# GD32EPRTxxA register map
File version: 1.0
CPU: CM33 r0p4, little endian, MPU, FPU, 4 interrupt priority bits
Registers are 32-bit, read-write, reset 0x0 unless marked. A register's access mark holds for its fields unless they carry their own. Offsets are from the block's base; [hi:lo] are bit positions; {n}, {i} and the like mark numbered series.

## SLAVE_TIMER3 — SHRTIMER Slave TIMER3 registers(
Base 0x40017600
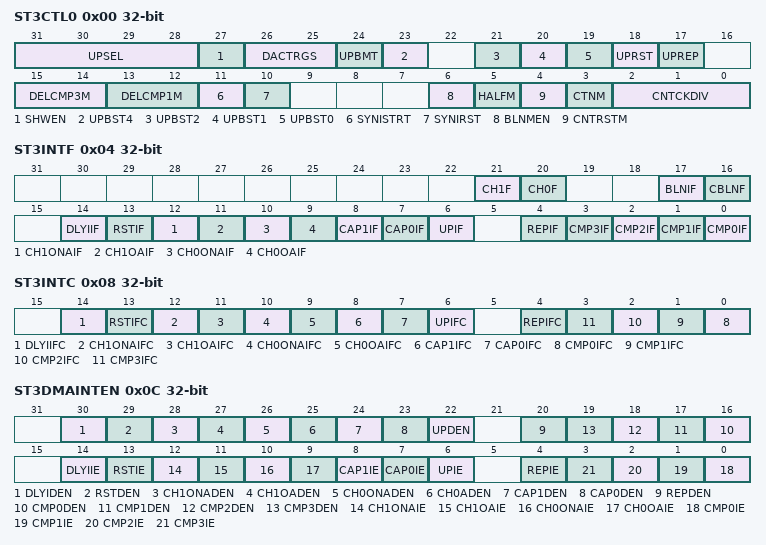
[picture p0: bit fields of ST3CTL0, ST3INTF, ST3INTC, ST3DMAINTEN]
0x00 ST3CTL0 — SHRTIMER Slave_TIMERx control register 0
  [31:28] UPSEL — Update event selection
  [27] SHWEN — Shadow registers enable
  [26:25] DACTRGS — Trigger source to DAC
  [24] UPBMT — Update by Master_TIMER update event
  [23] UPBST4 — Update by Slave_TIMER4 update event
  [21] UPBST2 — Update by Slave_TIMER2 update event
  [20] UPBST1 — Update by Slave_TIMER1 update event
  [19] UPBST0 — Update by Slave_TIMER0 update event
  [18] UPRST — Update event generated by reset event
  [17] UPREP — Update event generated by repetition event
  [15:14] DELCMP3M — Compare 3 delayed mode
  [13:12] DELCMP1M — Compare 1 delayed mode
  [11] SYNISTRT — Synchronization input start counter
  [10] SYNIRST — Synchronization input reset counter
  [6] BLNMEN — Balanced mode enable
  [5] HALFM — Half mode
  [4] CNTRSTM — Counter reset mode
  [3] CTNM — Continuous mode
  [2:0] CNTCKDIV — Counter clock division
0x04 ST3INTF ro — SHRTIMER Slave_TIMERx interrupt flag register
  [21] CH1F — Channel 1 output flag
  [20] CH0F — Channel 0 output flag
  [17] BLNIF — Balanced IDLE flag
  [16] CBLNF — Current balanced flag
  [14] DLYIIF — Delayed IDLE mode entry interrupt flag
  [13] RSTIF — Counter reset interrupt flag
  [12] CH1ONAIF — Channel 1 output inactive interrupt flag
  [11] CH1OAIF — Channel 1 output active interrupt flag
  [10] CH0ONAIF — Channel 0 output inactive interrupt flag
  [9] CH0OAIF — Channel 0 output active interrupt flag
  [8] CAP1IF — Capture 1 interrupt flag
  [7] CAP0IF — Capture 0 interrupt flag
  [6] UPIF — Update interrupt flag
  [4] REPIF — Repetition interrupt flag
  [n] CMP{n}IF (n=0..3) — Compare {n} interrupt flag
0x08 ST3INTC wo — SHRTIMER Slave_TIMERx interrupt flag clear register
  [14] DLYIIFC — Clear delayed IDLE mode entry interrupt flag
  [13] RSTIFC — Clear counter reset interrupt flag
  [12] CH1ONAIFC — Clear channel 1 output inactive interrupt flag
  [11] CH1OAIFC — Clear channel 1 output active interrupt flag
  [10] CH0ONAIFC — Clear channel 0 output inactive interrupt flag
  [9] CH0OAIFC — Clear channel 0 output active interrupt flag
  [8] CAP1IFC — Clear capture 1 interrupt flag
  [7] CAP0IFC — Clear capture 0 interrupt flag
  [6] UPIFC — Clear update interrupt flag
  [4] REPIFC — Clear repetition interrupt flag
  [n] CMP{n}IFC (n=0..3) — Clear compare {n} interrupt flag
0x0C ST3DMAINTEN — SHRTIMER Slave_TIMERx DMA and interrupt enable register
  [30] DLYIDEN — Delayed IDLE mode entry DMA request enable
  [29] RSTDEN — Counter reset DMA request enable
  [28] CH1ONADEN — Channel 1 output inactive DMA request enable
  [27] CH1OADEN — Channel 1 output active DMA request enable
  [26] CH0ONADEN — Channel 0 output inactive DMA request enable
  [25] CH0ADEN — Channel 0 output active DMA request enable
  [24] CAP1DEN — Capture 1 DMA request enable
  [23] CAP0DEN — Capture 0 DMA request enable
  [22] UPDEN — Update DMA request enable
  [20] REPDEN — Repetition DMA request enable
  [n+16] CMP{n}DEN (n=0..3) — Compare {n} DMA request enable
  [14] DLYIIE — Delayed IDLE mode entry interrupt enable
  [13] RSTIE — Counter reset interrupt enable
  [12] CH1ONAIE — Channel 1 output inactive interrupt enable
  [11] CH1OAIE — Channel 1 output active interrupt enable
  [10] CH0ONAIE — Channel 0 output inactive interrupt enable
  [9] CH0OAIE — Channel 0 output active interrupt enable
  [8] CAP1IE — Capture 1 interrupt enable
  [7] CAP0IE — Capture 0 interrupt enable
  [6] UPIE — Update interrupt enable
  [4] REPIE — Repetition interrupt enable
  [n] CMP{n}IE (n=0..3) — Compare {n} interrupt enable
0x10 ST3CNT — SHRTIMER Slave_TIMERx counter register
  [15:0] CNT — The current counter value
0x14 ST3CAR — SHRTIMER Slave_TIMER3 counter auto reload register
  [15:0] CARL — Counter auto reload value
0x18 ST3CREP — SHRTIMER Slave_TIMER3 counter repetition register
  [7:0] CREP — Counter repetition value
0x1C ST3CMP0V — SHRTIMER Slave_TIMER3 compare 0 value register
  [15:0] CMP0VAL — Compare 0 value
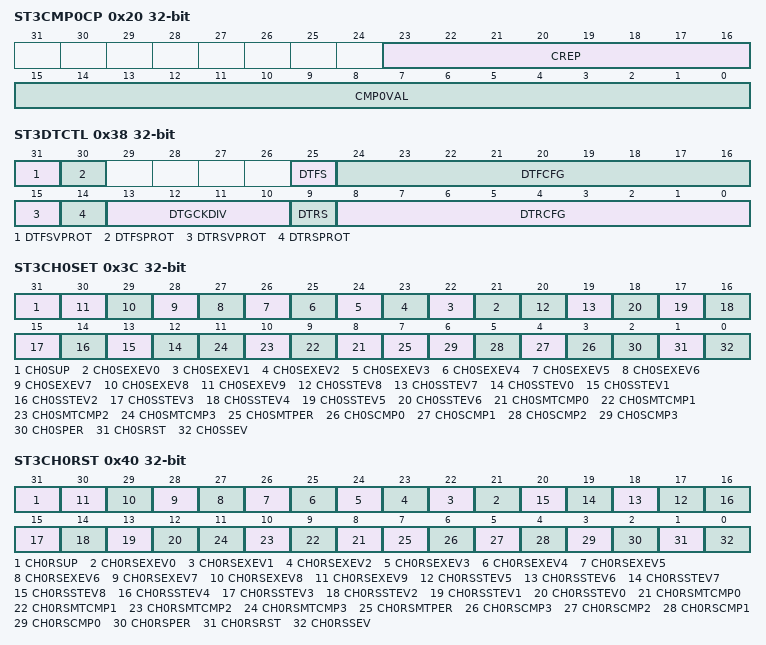
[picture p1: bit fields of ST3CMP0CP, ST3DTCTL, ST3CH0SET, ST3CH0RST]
0x20 ST3CMP0CP — SHRTIMER Slave_TIMERx compare 0 composite register
  [23:16] CREP — Counter repetition value
  [15:0] CMP0VAL — Compare 0 value
{0x20+4i} ST3CMP{i}V (i=1..3) — SHRTIMER Slave_TIMERx compare {i} value register
  [15:0] CMP{i}VAL — Compare {i} value
0x30 ST3CAP0V — SHRTIMER Slave_TIMERx capture 0 value register
  [15:0] CAP0VAL — Capture 0 value
0x34 ST3CAP1V — SHRTIMER Slave_TIMERx capture 1 value register
  [15:0] CAP1VAL — Capture 1 value
0x38 ST3DTCTL — SHRTIMER Slave_TIMERx dead-time control register
  [31] DTFSVPROT — Dead-time falling edge protection for value and sign
  [30] DTFSPROT — Dead-time falling edge protection for sign
  [25] DTFS — The sign of falling edge dead-time value
  [24:16] DTFCFG — Falling edge dead-time value
  [15] DTRSVPROT — Dead-time rising edge protection for value and sign
  [14] DTRSPROT — Dead-time rising edge protection for sign
  [13:10] DTGCKDIV — Dead time generator clock division
  [9] DTRS — The sign of falling edge dead-time value
  [8:0] DTRCFG — Falling edge dead-time value
0x3C ST3CH0SET — SHRTIMER Slave_TIMERx channel 0 set request register
  [31] CH0SUP — Update event generates channel 0
  [n+21] CH0SEXEV{n} (n=0..9) — External event {n} generates channel 0
  [20] CH0SSTEV8 — Slave_TIMERx interconnection event 8 generates channel 0
  [19] CH0SSTEV7 — Slave_TIMER1 interconnection event 7 generates channel 0
  [n+12] CH0SSTEV{n} (n=0..6) — Slave_TIMERx interconnection event {n} generates channel 0
  [n+8] CH0SMTCMP{n} (n=0..3) — Master_TIMER compare {n} event generates channel 0
  [7] CH0SMTPER — Master_TIMER period event generates channel 0
  [n+3] CH0SCMP{n} (n=0..3) — Slave_TIMERx compare {n} event generates channel 0
  [2] CH0SPER — Slave_TIMERx period event generates channel 0
  [1] CH0SRST — Slave_TIMERx reset event generates channel 0
  [0] CH0SSEV — Software event generates channel 0
0x40 ST3CH0RST — SHRTIMER Slave_TIMERx channel 0 reset request register
  [31] CH0RSUP — Update event generates channel 0
  [n+21] CH0RSEXEV{n} (n=0..9) — External event {n} generates channel 0
  [n+12] CH0RSSTEV{n} (n=5..8) — Slave_TIMERx interconnection event {n} generates channel 0
  [16] CH0RSSTEV4 — Slave_TIMER1 interconnection event 4 generates channel 0
  [15] CH0RSSTEV3 — Slave_TIMERx interconnection event 3 generates channel 0
  [14] CH0RSSTEV2 — Slave_TIMERx interconnection event 2 generates channel 0
  [13] CH0RSSTEV1 — Slave_TIMERx interconnection event 1 generates channel 0
  [12] CH0RSSTEV0 — Slave_TIMER1 interconnection event 0 generates channel 0
  [n+8] CH0RSMTCMP{n} (n=0..3) — Master_TIMER compare {n} event generates channel 0
  [7] CH0RSMTPER — Master_TIMER period event generates channel 0
  [6] CH0RSCMP3 — Slave_TIMERx compare 3 event generates channel 0
  [5] CH0RSCMP2 — Slave_TIMER1 compare 2 event generates channel 0
  [4] CH0RSCMP1 — Slave_TIMERx compare 1 event generates channel 0
  [3] CH0RSCMP0 — Slave_TIMERx compare 0 event generates channel 0
  [2] CH0RSPER — Slave_TIMERx period event generates channel 0
  [1] CH0RSRST — Slave_TIMERx reset event generates channel 0
  [0] CH0RSSEV — Software event generates channel 0
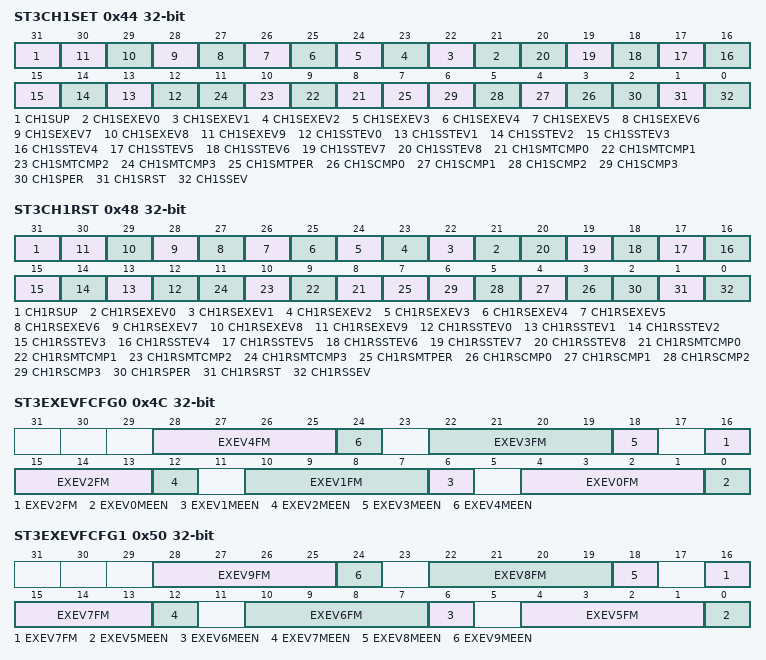
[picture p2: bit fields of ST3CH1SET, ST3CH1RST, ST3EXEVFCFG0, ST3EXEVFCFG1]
0x44 ST3CH1SET — SHRTIMER Slave_TIMERx channel 1 set request register
  [31] CH1SUP — Update event generates channel 1
  [n+21] CH1SEXEV{n} (n=0..9) — External event {n} generates channel 1
  [n+12] CH1SSTEV{n} (n=0..8) — Slave_TIMERx interconnection event {n} generates channel 1
  [n+8] CH1SMTCMP{n} (n=0..3) — Master_TIMER compare {n} event generates channel 1
  [7] CH1SMTPER — Master_TIMER period event generates channel 1
  [n+3] CH1SCMP{n} (n=0..3) — Slave_TIMERx compare {n} event generates channel 1
  [2] CH1SPER — Slave_TIMERx period event generates channel 1
  [1] CH1SRST — Slave_TIMERx reset event generates channel 1
  [0] CH1SSEV — Software event generates channel 1
0x48 ST3CH1RST — SHRTIMER Slave_TIMERx channel 1 reset request register
  [31] CH1RSUP — Update event generates channel 1
  [n+21] CH1RSEXEV{n} (n=0..9) — External event {n} generates channel 1
  [n+12] CH1RSSTEV{n} (n=0..8) — Slave_TIMERx interconnection event {n} generates channel 1
  [n+8] CH1RSMTCMP{n} (n=0..3) — Master_TIMER compare {n} event generates channel 1
  [7] CH1RSMTPER — Master_TIMER period event generates channel 1
  [n+3] CH1RSCMP{n} (n=0..3) — Slave_TIMERx compare {n} event generates channel 1
  [2] CH1RSPER — Slave_TIMERx period event generates channel 1
  [1] CH1RSRST — Slave_TIMERx reset event generates channel 1
  [0] CH1RSSEV — Software event generates channel 1
0x4C ST3EXEVFCFG0 — SHRTIMER Slave_TIMERx external event filter configuration register 0
  [6n+4:6n+1] EXEV{n}FM (n=0..4) — External event {n} filter mode
  [6n] EXEV{n}MEEN (n=0..4) — External event {n} memorized enable
0x50 ST3EXEVFCFG1 — SHRTIMER Slave_TIMERx external event filter configuration register 1
  [6n-26:6n-29] EXEV{n}FM (n=5..9) — External event {n} filter mode
  [6n-30] EXEV{n}MEEN (n=5..9) — External event {n} memorized enable
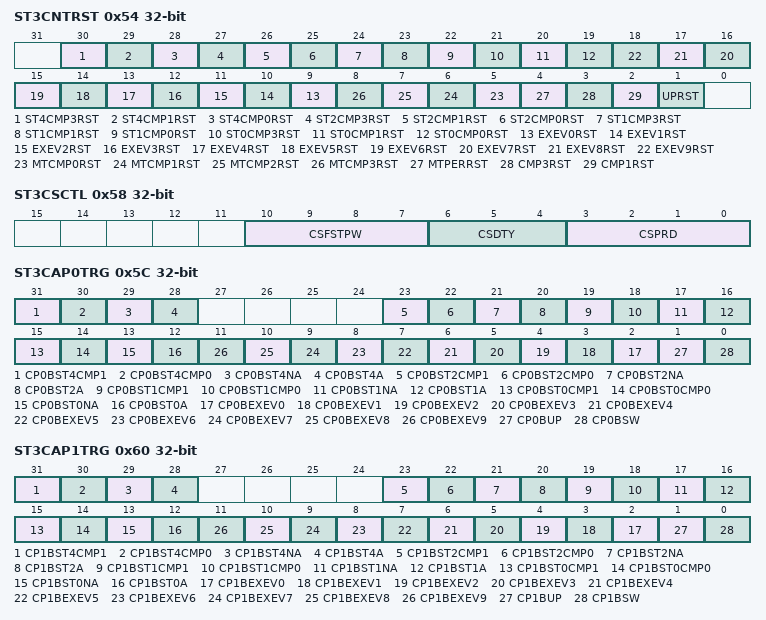
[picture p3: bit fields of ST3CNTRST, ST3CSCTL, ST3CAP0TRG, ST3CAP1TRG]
0x54 ST3CNTRST — SHRTIMER Slave_TIMERx counter reset register
  [30] ST4CMP3RST — Slave_TIMER4 compare 3 event resets counter
  [29] ST4CMP1RST — Slave_TIMER4 compare 1 event resets counter
  [28] ST4CMP0RST — Slave_TIMER4 compare 0 event resets counter
  [27] ST2CMP3RST — Slave_TIMER2 compare 3 event resets counter
  [26] ST2CMP1RST — Slave_TIMER2 compare 1 event resets counter
  [25] ST2CMP0RST — Slave_TIMER2 compare 0 event resets counter
  [24] ST1CMP3RST — Slave_TIMER1 compare 3 event resets counter
  [23] ST1CMP1RST — Slave_TIMER1 compare 1 event resets counter
  [22] ST1CMP0RST — Slave_TIMER1 compare 0 event resets counter
  [21] ST0CMP3RST — Slave_TIMER0 compare 3 event resets counter
  [20] ST0CMP1RST — Slave_TIMER0 compare 1 event resets counter
  [19] ST0CMP0RST — Slave_TIMER0 compare 0 event resets counter
  [n+9] EXEV{n}RST (n=0..9) — External event {n} resets counter
  [n+5] MTCMP{n}RST (n=0..3) — Master_TIMER compare {n} event resets counter
  [4] MTPERRST — Master_TIMER period event resets counter
  [3] CMP3RST — Slave_TIMERx compare 3 event resets counter
  [2] CMP1RST — Slave_TIMERx compare 1 event resets counter
  [1] UPRST — Slave_TIMERx update event resets counter
0x58 ST3CSCTL — SHRTIMER Slave_TIMERx carrier-signal control register
  [10:7] CSFSTPW — First carrier-signal pulse width
  [6:4] CSDTY — Carrier signal duty cycle
  [3:0] CSPRD — Carrier signal period
0x5C ST3CAP0TRG — SHRTIMER Slave_TIMERx capture 0 trigger register
  [31] CP0BST4CMP1 — Capture 0 triggered by compare 1 event of Slave_TIMER4
  [30] CP0BST4CMP0 — Capture 0 triggered by compare 0 event of Slave_TIMER4
  [29] CP0BST4NA — Capture 0 triggered by ST4CH0_O output active to inactive transition
  [28] CP0BST4A — Capture 0 triggered by ST4CH0_O output inactive to active transition
  [23] CP0BST2CMP1 — Capture 0 triggered by compare 1 event of Slave_TIMER2
  [22] CP0BST2CMP0 — Capture 0 triggered by compare 0 event of Slave_TIMER2
  [21] CP0BST2NA — Capture 0 triggered by ST2CH0_O output active to inactive transition
  [20] CP0BST2A — Capture 0 triggered by ST2CH0_O output inactive to active transition
  [19] CP0BST1CMP1 — Capture 0 triggered by compare 1 event of Slave_TIMER1
  [18] CP0BST1CMP0 — Capture 0 triggered by compare 0 event of Slave_TIMER1
  [17] CP0BST1NA — Capture 0 triggered by ST2CH1_O output active to inactive transition
  [16] CP0BST1A — Capture 0 triggered by ST2CH1_O output inactive to active transition
  [15] CP0BST0CMP1 — Capture 0 triggered by compare 1 event of Slave_TIMER0
  [14] CP0BST0CMP0 — Capture 0 triggered by compare 0 event of Slave_TIMER0
  [13] CP0BST0NA — Capture 0 triggered by ST0CH0_O output active to inactive transition
  [12] CP0BST0A — Capture 0 triggered by ST0CH0_O output inactive to active transition
  [n+2] CP0BEXEV{n} (n=0..9) — Capture 0 triggered by external event {n}
  [1] CP0BUP — Capture 0 triggered by update event
  [0] CP0BSW — Capture 0 triggered by software
0x60 ST3CAP1TRG — SHRTIMER Slave_TIMERx capture 1 trigger register
  [31] CP1BST4CMP1 — Capture 1 triggered by compare 1 event of Slave_TIMER4
  [30] CP1BST4CMP0 — Capture 1 triggered by compare 0 event of Slave_TIMER4
  [29] CP1BST4NA — Capture 1 triggered by ST4CH0_O output active to inactive transition
  [28] CP1BST4A — Capture 1 triggered by ST4CH0_O output inactive to active transition
  [23] CP1BST2CMP1 — Capture 1 triggered by compare 1 event of Slave_TIMER2
  [22] CP1BST2CMP0 — Capture 1 triggered by compare 0 event of Slave_TIMER2
  [21] CP1BST2NA — Capture 1 triggered by ST2CH0_O output active to inactive transition
  [20] CP1BST2A — Capture 1 triggered by ST2CH0_O output inactive to active transition
  [19] CP1BST1CMP1 — Capture 1 triggered by compare 1 event of Slave_TIMER1
  [18] CP1BST1CMP0 — Capture 1 triggered by compare 0 event of Slave_TIMER1
  [17] CP1BST1NA — Capture 1 triggered by ST2CH1_O output active to inactive transition
  [16] CP1BST1A — Capture 1 triggered by ST2CH1_O output inactive to active transition
  [15] CP1BST0CMP1 — Capture 1 triggered by compare 1 event of Slave_TIMER0
  [14] CP1BST0CMP0 — Capture 1 triggered by compare 0 event of Slave_TIMER0
  [13] CP1BST0NA — Capture 1 triggered by ST0CH0_O output active to inactive transition
  [12] CP1BST0A — Capture 1 triggered by ST0CH0_O output inactive to active transition
  [n+2] CP1BEXEV{n} (n=0..9) — Capture 1 triggered by external event {n}
  [1] CP1BUP — Capture 1 triggered by update event
  [0] CP1BSW — Capture 1 triggered by software
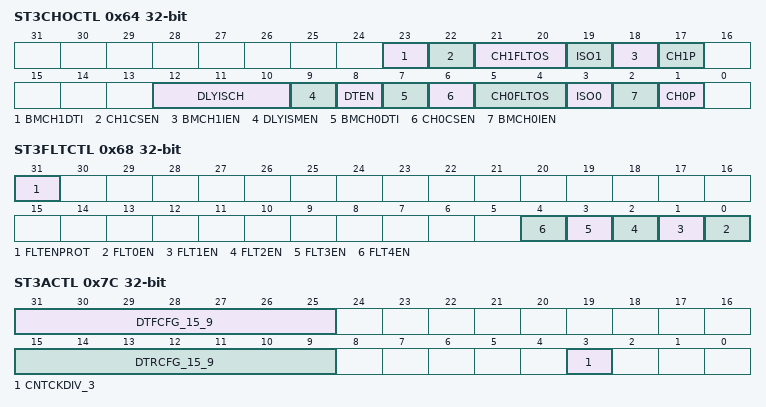
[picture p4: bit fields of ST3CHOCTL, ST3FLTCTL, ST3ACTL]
0x64 ST3CHOCTL — SHRTIMER Slave_TIMERx channel output control register
  [23] BMCH1DTI — Channel 1 dead-time insert in bunch mode
  [22] CH1CSEN — Channel 1 carrier-signal mode enable
  [21:20] CH1FLTOS — Channel 1 Fault output state
  [19] ISO1 — channel 1 output idle state
  [18] BMCH1IEN — Channel 1 IDLE state enable in bunch mode
  [17] CH1P — Channel 1 output polarity
  [12:10] DLYISCH — Delayed IDLE source and channel
  [9] DLYISMEN — Delayed IDLE state mode enable
  [8] DTEN — Dead time enable
  [7] BMCH0DTI — Channel 0 dead-time insert in bunch mode
  [6] CH0CSEN — Channel 0 carrier-signal mode enable
  [5:4] CH0FLTOS — Channel 0 Fault output state
  [3] ISO0 — Channel 0 output idle state
  [2] BMCH0IEN — Channel 0 IDLE state enable in bunch mode
  [1] CH0P — Channel 0 output polarity
0x68 ST3FLTCTL — SHRTIMER Slave_TIMERx fault control register
  [31] FLTENPROT — Protect fault enable
  [n] FLT{n}EN (n=0..4) — Fault {n} enable
0x7C ST3ACTL — SHRTIMER Slave_TIMERx additional control register
  [31:25] DTFCFG_15_9 — Falling edge dead-time value configure
  [15:9] DTRCFG_15_9 — Rising edge dead-time value configure
  [3] CNTCKDIV_3 — Counter clock division
